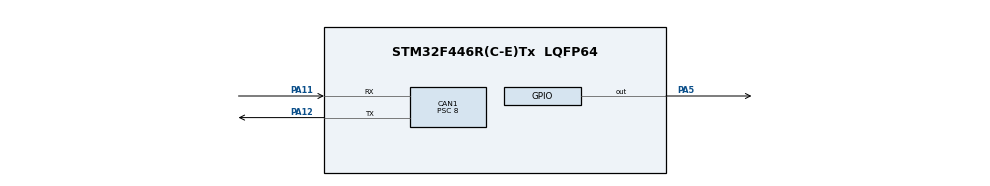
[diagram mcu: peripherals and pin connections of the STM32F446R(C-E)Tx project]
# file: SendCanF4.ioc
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CAN1.BS1=CAN_BS1_13TQ
CAN1.BS2=CAN_BS2_2TQ
CAN1.CalculateBaudRate=125000
CAN1.CalculateTimeBit=8000
CAN1.CalculateTimeQuantum=500.0
CAN1.Mode=CAN_MODE_NORMAL
CAN1.NART=ENABLE
CAN1.Prescaler=8
Mcu.Family=STM32F4
Mcu.Name=STM32F446R(C-E)Tx
Mcu.Package=LQFP64
NVIC.CAN1_RX0_IRQn=true\:0\:0\:false\:false\:true\:true\:true\:true
NVIC.CAN1_RX1_IRQn=true\:0\:0\:false\:false\:true\:true\:true\:true
NVIC.CAN1_SCE_IRQn=true\:0\:0\:false\:false\:true\:true\:true\:true
NVIC.CAN1_TX_IRQn=true\:0\:0\:false\:false\:true\:true\:true\:true
NVIC.PriorityGroup=NVIC_PRIORITYGROUP_4
PA11.Mode=CAN_Activate
PA11.Signal=CAN1_RX
PA12.Mode=CAN_Activate
PA12.Signal=CAN1_TX
PA5.Signal=GPIO_Output
ProjectManager.HeapSize=0x200
ProjectManager.StackSize=0x400
ProjectManager.TargetToolchain=STM32CubeIDE
RCC.CortexFreq_Value=16000000
RCC.USBFreq_Value=96000000
RCC.VCOOutputFreq_Value=192000000
board=custom

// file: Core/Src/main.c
/* USER CODE BEGIN Header */
/**
  ******************************************************************************
  * @file           : main.c
  * @brief          : Main program body
  ******************************************************************************
  * @attention
  *
  * Copyright (c) 2025 STMicroelectronics.
  * All rights reserved.
  *
  * This software is licensed under terms that can be found in the LICENSE file
  * in the root directory of this software component.
  * If no LICENSE file comes with this software, it is provided AS-IS.
  *
  ******************************************************************************
  */
/* USER CODE END Header */
#include "main.h"

CAN_HandleTypeDef hcan1;

void SystemClock_Config(void);
static void MX_GPIO_Init(void);
static void MX_CAN1_Init(void);

int main(void)
{

  /* MCU Configuration--------------------------------------------------------*/

  /* Reset of all peripherals, Initializes the Flash interface and the Systick. */
  HAL_Init();

  /* Configure the system clock */
  SystemClock_Config();

  /* Initialize all configured peripherals */
  MX_GPIO_Init();
  MX_CAN1_Init();
  /* USER CODE BEGIN 2 */

  HAL_CAN_Start(&hcan1);
  HAL_CAN_ActivateNotification(&hcan1, CAN_IT_RX_FIFO0_MSG_PENDING);
  /* USER CODE END 2 */

  /* Infinite loop */
  while (1)
  {

    /* USER CODE BEGIN 3 */
	  send_can_heartbeat();
	  HAL_Delay(1000);
  }
  /* USER CODE END 3 */
}

void SystemClock_Config(void)
{
  RCC_OscInitTypeDef RCC_OscInitStruct = {0};
  RCC_ClkInitTypeDef RCC_ClkInitStruct = {0};

  /** Configure the main internal regulator output voltage
  */
  __HAL_RCC_PWR_CLK_ENABLE();
  __HAL_PWR_VOLTAGESCALING_CONFIG(PWR_REGULATOR_VOLTAGE_SCALE3);

  /** Initializes the RCC Oscillators according to the specified parameters
  * in the RCC_OscInitTypeDef structure.
  */
  RCC_OscInitStruct.OscillatorType = RCC_OSCILLATORTYPE_HSI;
  RCC_OscInitStruct.HSIState = RCC_HSI_ON;
  RCC_OscInitStruct.HSICalibrationValue = RCC_HSICALIBRATION_DEFAULT;
  RCC_OscInitStruct.PLL.PLLState = RCC_PLL_NONE;
  if (HAL_RCC_OscConfig(&RCC_OscInitStruct) != HAL_OK)
  {
    Error_Handler();
  }

  /** Initializes the CPU, AHB and APB buses clocks
  */
  RCC_ClkInitStruct.ClockType = RCC_CLOCKTYPE_HCLK|RCC_CLOCKTYPE_SYSCLK
                              |RCC_CLOCKTYPE_PCLK1|RCC_CLOCKTYPE_PCLK2;
  RCC_ClkInitStruct.SYSCLKSource = RCC_SYSCLKSOURCE_HSI;
  RCC_ClkInitStruct.AHBCLKDivider = RCC_SYSCLK_DIV1;
  RCC_ClkInitStruct.APB1CLKDivider = RCC_HCLK_DIV1;
  RCC_ClkInitStruct.APB2CLKDivider = RCC_HCLK_DIV1;

  if (HAL_RCC_ClockConfig(&RCC_ClkInitStruct, FLASH_LATENCY_0) != HAL_OK)
  {
    Error_Handler();
  }
}

static void MX_CAN1_Init(void)
{

  /* USER CODE BEGIN CAN1_Init 0 */
  __HAL_RCC_CAN1_CLK_ENABLE();
  /* USER CODE END CAN1_Init 0 */

  hcan1.Instance = CAN1;
  hcan1.Init.Prescaler = 8;
  hcan1.Init.Mode = CAN_MODE_NORMAL;
  hcan1.Init.SyncJumpWidth = CAN_SJW_1TQ;
  hcan1.Init.TimeSeg1 = CAN_BS1_13TQ;
  hcan1.Init.TimeSeg2 = CAN_BS2_2TQ;
  hcan1.Init.TimeTriggeredMode = DISABLE;
  hcan1.Init.AutoBusOff = DISABLE;
  hcan1.Init.AutoWakeUp = DISABLE;
  hcan1.Init.AutoRetransmission = ENABLE;
  hcan1.Init.ReceiveFifoLocked = DISABLE;
  hcan1.Init.TransmitFifoPriority = DISABLE;
  if (HAL_CAN_Init(&hcan1) != HAL_OK)
  {
    Error_Handler();
  }
  /* USER CODE BEGIN CAN1_Init 2 */
  CAN_FilterTypeDef sFilterConfig = {0};
  sFilterConfig.FilterBank = 0;
  sFilterConfig.FilterMode = CAN_FILTERMODE_IDMASK;
  sFilterConfig.FilterScale = CAN_FILTERSCALE_32BIT;
  sFilterConfig.FilterIdHigh = 0x0000;
  sFilterConfig.FilterIdLow  = 0x0000;
  sFilterConfig.FilterMaskIdHigh = 0x0000;
  sFilterConfig.FilterMaskIdLow  = 0x0000;
  sFilterConfig.FilterFIFOAssignment = CAN_RX_FIFO0;
  sFilterConfig.FilterActivation = ENABLE;
  sFilterConfig.SlaveStartFilterBank = 13;
  if (HAL_CAN_ConfigFilter(&hcan1, &sFilterConfig) != HAL_OK) {
      Error_Handler();
  }
  /* USER CODE END CAN1_Init 2 */

}

static void MX_GPIO_Init(void)
{
  GPIO_InitTypeDef GPIO_InitStruct = {0};

  /* GPIO Ports Clock Enable */
  __HAL_RCC_GPIOA_CLK_ENABLE();

  /*Configure GPIO pin Output Level */
  HAL_GPIO_WritePin(GPIOA, GPIO_PIN_5, GPIO_PIN_RESET);

  /*Configure GPIO pin : PA5 */
  GPIO_InitStruct.Pin = GPIO_PIN_5;
  GPIO_InitStruct.Mode = GPIO_MODE_OUTPUT_PP;
  GPIO_InitStruct.Pull = GPIO_NOPULL;
  GPIO_InitStruct.Speed = GPIO_SPEED_FREQ_LOW;
  HAL_GPIO_Init(GPIOA, &GPIO_InitStruct);

  /* USER CODE BEGIN MX_GPIO_Init_2 */
  GPIO_InitStruct.Pin       = GPIO_PIN_11 | GPIO_PIN_12;
  GPIO_InitStruct.Mode      = GPIO_MODE_AF_PP;
  GPIO_InitStruct.Pull      = GPIO_NOPULL;
  GPIO_InitStruct.Speed     = GPIO_SPEED_FREQ_VERY_HIGH;
  GPIO_InitStruct.Alternate = GPIO_AF9_CAN1;
  HAL_GPIO_Init(GPIOA, &GPIO_InitStruct);
  HAL_NVIC_SetPriority(CAN1_RX0_IRQn, 0, 0);
  HAL_NVIC_EnableIRQ(CAN1_RX0_IRQn);
  /* USER CODE END MX_GPIO_Init_2 */
}

/* USER CODE BEGIN 4 */
void HAL_CAN_RxFifo0MsgPendingCallback(CAN_HandleTypeDef *hcan) {
    CAN_RxHeaderTypeDef rxHeader;
    uint8_t rxData[8];

    if (HAL_CAN_GetRxMessage(hcan, CAN_RX_FIFO0, &rxHeader, rxData) == HAL_OK) {
    	HAL_GPIO_TogglePin(GPIOA, GPIO_PIN_5);
    }
}

void send_can_heartbeat(void)
{
  CAN_TxHeaderTypeDef txHeader = {0};
  uint8_t txData[4] = {0xDE,0xAD,0xBE,0xEF};
  uint32_t txMailbox;

  txHeader.StdId = 0x123;
  txHeader.IDE   = CAN_ID_STD;
  txHeader.RTR   = CAN_RTR_DATA;
  txHeader.DLC   = 4;

  if (HAL_CAN_AddTxMessage(&hcan1, &txHeader, txData, &txMailbox) != HAL_OK)
    Error_Handler();
}
/* USER CODE END 4 */

void Error_Handler(void)
{
  __disable_irq();
  while (1)
  {
  }
}
